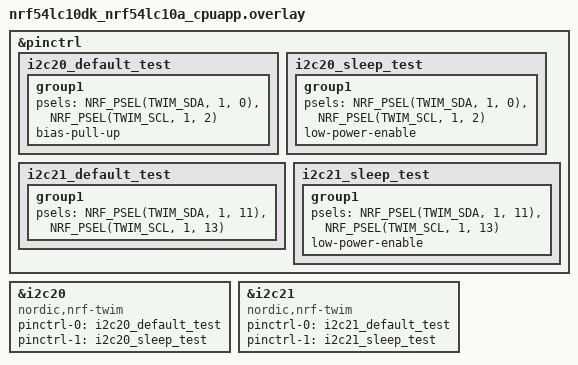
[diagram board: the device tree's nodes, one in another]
/*
 * Copyright (c) 2026 Nordic Semiconductor ASA
 *
 * SPDX-License-Identifier: LicenseRef-Nordic-5-Clause
 *
 * nRF54LC10 DK: P1.8 / P1.10 are used by buttons / LED — use P1.11 / P1.13 for second TWIM.
 */

&pinctrl {
	i2c20_default_test: i2c20_default_test {
		group1 {
			psels = <NRF_PSEL(TWIM_SDA, 1, 0)>,
				<NRF_PSEL(TWIM_SCL, 1, 2)>;
			bias-pull-up;
		};
	};

	i2c20_sleep_test: i2c20_sleep_test {
		group1 {
			psels = <NRF_PSEL(TWIM_SDA, 1, 0)>,
				<NRF_PSEL(TWIM_SCL, 1, 2)>;
			low-power-enable;
		};
	};

	i2c21_default_test: i2c21_default_test {
		group1 {
			psels = <NRF_PSEL(TWIM_SDA, 1, 11)>,
				<NRF_PSEL(TWIM_SCL, 1, 13)>;
		};
	};

	i2c21_sleep_test: i2c21_sleep_test {
		group1 {
			psels = <NRF_PSEL(TWIM_SDA, 1, 11)>,
				<NRF_PSEL(TWIM_SCL, 1, 13)>;
			low-power-enable;
		};
	};
};

&i2c20 {
	compatible = "nordic,nrf-twim";
	status = "okay";
	pinctrl-0 = <&i2c20_default_test>;
	pinctrl-1 = <&i2c20_sleep_test>;
	pinctrl-names = "default", "sleep";
};

&i2c21 {
	compatible = "nordic,nrf-twim";
	status = "okay";
	pinctrl-0 = <&i2c21_default_test>;
	pinctrl-1 = <&i2c21_sleep_test>;
	pinctrl-names = "default", "sleep";
};

/* i2c30 inaccessible due to console on uart30 */
